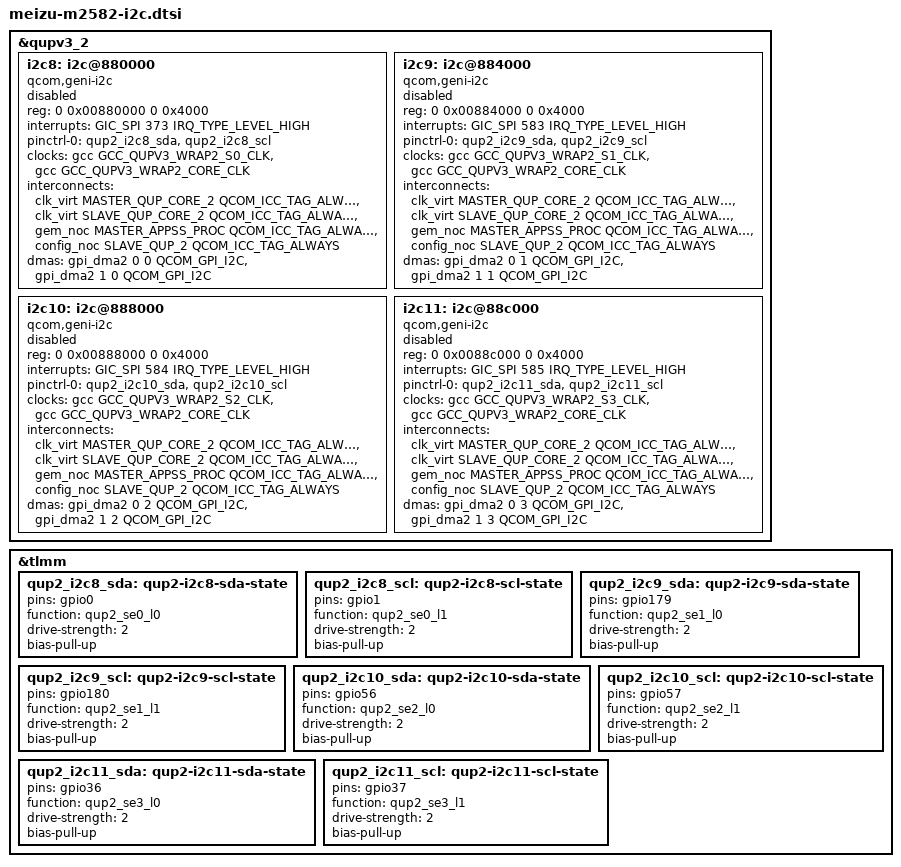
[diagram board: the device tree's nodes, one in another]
// SPDX-License-Identifier: BSD-3-Clause
/*
 * Meizu 22 (M2582) -- QUPV3 wrap 2 I2C controllers (0x8c0000).
 *
 * The qup-core interconnect vote (MASTER_QUP_CORE_2 -> SLAVE_QUP_CORE_2) is
 * required to ungate the wrap-2 core clock before the first register transfer.
 * SE8 (i2c8 @0x880000) reports FIFO_IF_DISABLE and requires gpi_dma2.
 * On hw_version 6, SE8 carries camera EEPROM/sensor (0x50/0x36), SE9 carries
 * et5907 (0x35) + 0x77, SE10 (gpio56/57) is owned by ADSP, and SE11 carries
 * et5907 (0x35) + aw20054 (0x3a).
 */

#include <dt-bindings/dma/qcom-gpi.h>

&qupv3_2 {
	/*
	 * SE8's pads are gpio0/gpio1. pinctrl-tuna.c: qup2_se0_l0 -> gpio0,
	 * qup2_se0_l1 -> gpio1.
	 */
	i2c8: i2c@880000 {
		compatible = "qcom,geni-i2c";
		reg = <0 0x00880000 0 0x4000>;
		interrupts = <GIC_SPI 373 IRQ_TYPE_LEVEL_HIGH>;
		pinctrl-names = "default";
		pinctrl-0 = <&qup2_i2c8_sda>, <&qup2_i2c8_scl>;
		clocks = <&gcc GCC_QUPV3_WRAP2_S0_CLK>, <&gcc GCC_QUPV3_WRAP2_CORE_CLK>;
		interconnects = <&clk_virt MASTER_QUP_CORE_2 QCOM_ICC_TAG_ALWAYS
				 &clk_virt SLAVE_QUP_CORE_2 QCOM_ICC_TAG_ALWAYS>,
				<&gem_noc MASTER_APPSS_PROC QCOM_ICC_TAG_ALWAYS
				 &config_noc SLAVE_QUP_2 QCOM_ICC_TAG_ALWAYS>;
		interconnect-names = "qup-core", "qup-config";
		clock-names = "se", "core";
		dmas = <&gpi_dma2 0 0 QCOM_GPI_I2C>,
		       <&gpi_dma2 1 0 QCOM_GPI_I2C>;
		dma-names = "tx", "rx";
		#address-cells = <1>;
		#size-cells = <0>;
		status = "disabled";
	};

	/* SE9: gpio179/gpio180 (qup2_se1_l0/l1). */
	i2c9: i2c@884000 {
		compatible = "qcom,geni-i2c";
		reg = <0 0x00884000 0 0x4000>;
		interrupts = <GIC_SPI 583 IRQ_TYPE_LEVEL_HIGH>;
		pinctrl-names = "default";
		pinctrl-0 = <&qup2_i2c9_sda>, <&qup2_i2c9_scl>;
		clocks = <&gcc GCC_QUPV3_WRAP2_S1_CLK>, <&gcc GCC_QUPV3_WRAP2_CORE_CLK>;
		interconnects = <&clk_virt MASTER_QUP_CORE_2 QCOM_ICC_TAG_ALWAYS
				 &clk_virt SLAVE_QUP_CORE_2 QCOM_ICC_TAG_ALWAYS>,
				<&gem_noc MASTER_APPSS_PROC QCOM_ICC_TAG_ALWAYS
				 &config_noc SLAVE_QUP_2 QCOM_ICC_TAG_ALWAYS>;
		interconnect-names = "qup-core", "qup-config";
		clock-names = "se", "core";
		dmas = <&gpi_dma2 0 1 QCOM_GPI_I2C>,
		       <&gpi_dma2 1 1 QCOM_GPI_I2C>;
		dma-names = "tx", "rx";
		#address-cells = <1>;
		#size-cells = <0>;
		status = "disabled";
	};

	/* SE10: gpio56/gpio57 (qup2_se2_l0/l1). The board's fuel gauge is here. */
	i2c10: i2c@888000 {
		compatible = "qcom,geni-i2c";
		reg = <0 0x00888000 0 0x4000>;
		interrupts = <GIC_SPI 584 IRQ_TYPE_LEVEL_HIGH>;
		pinctrl-names = "default";
		pinctrl-0 = <&qup2_i2c10_sda>, <&qup2_i2c10_scl>;
		clocks = <&gcc GCC_QUPV3_WRAP2_S2_CLK>, <&gcc GCC_QUPV3_WRAP2_CORE_CLK>;
		interconnects = <&clk_virt MASTER_QUP_CORE_2 QCOM_ICC_TAG_ALWAYS
				 &clk_virt SLAVE_QUP_CORE_2 QCOM_ICC_TAG_ALWAYS>,
				<&gem_noc MASTER_APPSS_PROC QCOM_ICC_TAG_ALWAYS
				 &config_noc SLAVE_QUP_2 QCOM_ICC_TAG_ALWAYS>;
		interconnect-names = "qup-core", "qup-config";
		clock-names = "se", "core";
		dmas = <&gpi_dma2 0 2 QCOM_GPI_I2C>,
		       <&gpi_dma2 1 2 QCOM_GPI_I2C>;
		dma-names = "tx", "rx";
		#address-cells = <1>;
		#size-cells = <0>;
		status = "disabled";
	};

	/* SE11: gpio36/gpio37 (qup2_se3_l0/l1). */
	i2c11: i2c@88c000 {
		compatible = "qcom,geni-i2c";
		reg = <0 0x0088c000 0 0x4000>;
		interrupts = <GIC_SPI 585 IRQ_TYPE_LEVEL_HIGH>;
		pinctrl-names = "default";
		pinctrl-0 = <&qup2_i2c11_sda>, <&qup2_i2c11_scl>;
		clocks = <&gcc GCC_QUPV3_WRAP2_S3_CLK>, <&gcc GCC_QUPV3_WRAP2_CORE_CLK>;
		interconnects = <&clk_virt MASTER_QUP_CORE_2 QCOM_ICC_TAG_ALWAYS
				 &clk_virt SLAVE_QUP_CORE_2 QCOM_ICC_TAG_ALWAYS>,
				<&gem_noc MASTER_APPSS_PROC QCOM_ICC_TAG_ALWAYS
				 &config_noc SLAVE_QUP_2 QCOM_ICC_TAG_ALWAYS>;
		interconnect-names = "qup-core", "qup-config";
		clock-names = "se", "core";
		dmas = <&gpi_dma2 0 3 QCOM_GPI_I2C>,
		       <&gpi_dma2 1 3 QCOM_GPI_I2C>;
		dma-names = "tx", "rx";
		#address-cells = <1>;
		#size-cells = <0>;
		status = "disabled";
	};
};

&tlmm {
	qup2_i2c8_sda: qup2-i2c8-sda-state {
		pins = "gpio0";
		function = "qup2_se0_l0";
		drive-strength = <2>;
		bias-pull-up;
	};

	qup2_i2c8_scl: qup2-i2c8-scl-state {
		pins = "gpio1";
		function = "qup2_se0_l1";
		drive-strength = <2>;
		bias-pull-up;
	};

	qup2_i2c9_sda: qup2-i2c9-sda-state {
		pins = "gpio179";
		function = "qup2_se1_l0";
		drive-strength = <2>;
		bias-pull-up;
	};

	qup2_i2c9_scl: qup2-i2c9-scl-state {
		pins = "gpio180";
		function = "qup2_se1_l1";
		drive-strength = <2>;
		bias-pull-up;
	};

	qup2_i2c10_sda: qup2-i2c10-sda-state {
		pins = "gpio56";
		function = "qup2_se2_l0";
		drive-strength = <2>;
		bias-pull-up;
	};

	qup2_i2c10_scl: qup2-i2c10-scl-state {
		pins = "gpio57";
		function = "qup2_se2_l1";
		drive-strength = <2>;
		bias-pull-up;
	};

	qup2_i2c11_sda: qup2-i2c11-sda-state {
		pins = "gpio36";
		function = "qup2_se3_l0";
		drive-strength = <2>;
		bias-pull-up;
	};

	qup2_i2c11_scl: qup2-i2c11-scl-state {
		pins = "gpio37";
		function = "qup2_se3_l1";
		drive-strength = <2>;
		bias-pull-up;
	};
};

/*
 * The touchscreen is not on an I2C bus at all: SE4 is SPI on this board, and
 * the part on it is a Synaptics TCM controller.  Both the bus and the device
 * live in meizu-m2582-touch.dtsi.
 */
